AUTOSAR XML (schema 4-0-3)
standard types defined: Boolean, UInt32
package /AUTOSAR_Platform/DataConstrs
  range DC_Boolean: raw 0..1
package /PATAC/MSM/ComponentTypes
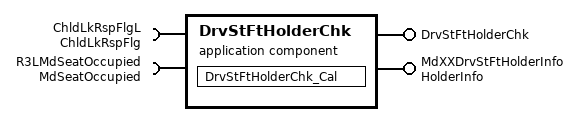
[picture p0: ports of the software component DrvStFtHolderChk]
  application sw component type DrvStFtHolderChk
    provide port DrvStFtHolderChk: server-com-spec{operation=Cal, queue-length=1}, provided-interface=DrvStFtHolderChk
    provide port MdXXDrvStFtHolderInfo: nonqueued-sender-com-spec{data-element=HolderInfo/Val, init-value=0}, provided-interface=HolderInfo
    require port ChldLkRspFlgL: nonqueued-receiver-com-spec{data-element=ChldLkRspFlg/Val, filter=data-filter-type=ALWAYS, init-value=0}, required-interface=ChldLkRspFlg
    require port R3LMdSeatOccupied: nonqueued-receiver-com-spec{data-element=MdSeatOccupied/Val, filter=data-filter-type=ALWAYS, init-value=0}, required-interface=MdSeatOccupied
    behavior DrvStFtHolderChk_InternalBehavior
      operation invoked event OIT_DrvStFtHolderChk_Cal_DrvStFtHolderChk_Cal: start-on-event=DrvStFtHolderChk_Cal, operation=DrvStFtHolderChk.Cal
      runnable DrvStFtHolderChk_Cal
        data-receive-point-by-arguments:
          access REC_ChldLkRspFlgL_Val: accessed-variable=ChldLkRspFlgL.Val
          access REC_R3LMdSeatOccupied_Val: accessed-variable=R3LMdSeatOccupied.Val
        data-send-points:
          access SEND_MdXXDrvStFtHolderInfo_Val: accessed-variable=MdXXDrvStFtHolderInfo.Val
  swc implementation DrvStFtHolderChk_Implementation: behavior=DrvStFtHolderChk_InternalBehavior
    code-descriptors:
      code Default: artifact-descriptors=autosar-engineering-object={short-label=Default, category=SWSRC}
package /PATAC/MSM/ModeAdjust/PortInterface
  client server interface DrvStFtHolderChk
    operation Cal
  sender receiver interface ChldLkRspFlg: invalidation-policy{data-element=ChldLkRspFlg/Val, handle-invalid=DONT-INVALIDATE}
    data Val: type=Boolean
  sender receiver interface HolderInfo: invalidation-policy{data-element=HolderInfo/Val, handle-invalid=DONT-INVALIDATE}
    data Val: type=UInt32
  sender receiver interface MdSeatOccupied: invalidation-policy{data-element=MdSeatOccupied/Val, handle-invalid=DONT-INVALIDATE}
    data Val: type=Boolean
